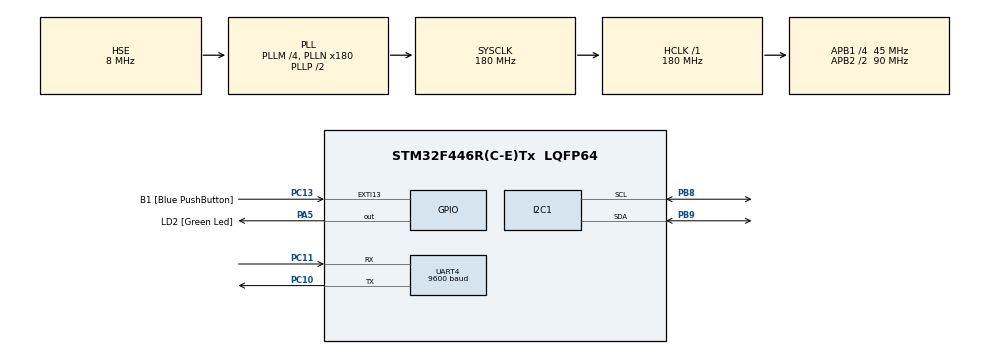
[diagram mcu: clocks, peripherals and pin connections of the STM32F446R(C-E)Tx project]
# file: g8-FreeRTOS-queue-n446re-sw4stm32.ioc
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Dma.Request0=UART4_RX
Dma.UART4_RX.0.Direction=DMA_PERIPH_TO_MEMORY
Dma.UART4_RX.0.FIFOMode=DMA_FIFOMODE_DISABLE
Dma.UART4_RX.0.Instance=DMA1_Stream2
Dma.UART4_RX.0.MemDataAlignment=DMA_MDATAALIGN_BYTE
Dma.UART4_RX.0.MemInc=DMA_MINC_ENABLE
Dma.UART4_RX.0.Mode=DMA_CIRCULAR
Dma.UART4_RX.0.PeriphDataAlignment=DMA_PDATAALIGN_BYTE
Dma.UART4_RX.0.PeriphInc=DMA_PINC_DISABLE
Dma.UART4_RX.0.Priority=DMA_PRIORITY_LOW
FREERTOS.Queues01=mailYPR,16,uint16_t,0,Dynamic,NULL,NULL;mailCMD,16,uint16_t,0,Dynamic,NULL,NULL
FREERTOS.Tasks01=defaultTask,0,128,StartDefaultTask,Default,NULL,Dynamic,NULL,NULL;readSensors,2,512,StartReadSensors,Default,NULL,Dynamic,NULL,NULL;drawBox,-2,512,StartDrawBox,Default,NULL,Dynamic,NULL,NULL;waitCommand,-2,512,StartWaitCommand,Default,NULL,Dynamic,NULL,NULL
I2C1.I2C_Mode=I2C_Fast
Mcu.Family=STM32F4
Mcu.Name=STM32F446R(C-E)Tx
Mcu.Package=LQFP64
NVIC.DMA1_Stream2_IRQn=true\:5\:0\:false\:false\:true\:true\:false
NVIC.PriorityGroup=NVIC_PRIORITYGROUP_4
NVIC.TIM6_DAC_IRQn=true\:0\:0\:false\:false\:true\:false\:false
NVIC.TimeBase=TIM6_DAC_IRQn
NVIC.TimeBaseIP=TIM6
PA13.GPIO_Label=TMS
PA13.Mode=Serial_Wire
PA13.Signal=SYS_JTMS-SWDIO
PA14.GPIO_Label=TCK
PA14.Mode=Serial_Wire
PA14.Signal=SYS_JTCK-SWCLK
PA5.GPIO_Label=LD2 [Green Led]
PA5.Signal=GPIO_Output
PB3.GPIO_Label=SWO
PB3.Signal=SYS_JTDO-SWO
PB8.Mode=I2C
PB8.Signal=I2C1_SCL
PB9.Mode=I2C
PB9.Signal=I2C1_SDA
PC10.Mode=Asynchronous
PC10.Signal=UART4_TX
PC11.Mode=Asynchronous
PC11.Signal=UART4_RX
PC13.GPIO_Label=B1 [Blue PushButton]
PC13.GPIO_ModeDefaultEXTI=GPIO_MODE_IT_FALLING
PC13.Signal=GPXTI13
PC14-OSC32_IN.Mode=LSE-External-Oscillator
PC14-OSC32_IN.Signal=RCC_OSC32_IN
PC15-OSC32_OUT.Mode=LSE-External-Oscillator
PC15-OSC32_OUT.Signal=RCC_OSC32_OUT
PH0-OSC_IN.Mode=HSE-External-Oscillator
PH0-OSC_IN.Signal=RCC_OSC_IN
PH1-OSC_OUT.Mode=HSE-External-Oscillator
PH1-OSC_OUT.Signal=RCC_OSC_OUT
ProjectManager.HeapSize=0x200
ProjectManager.StackSize=0x400
ProjectManager.TargetToolchain=SW4STM32
RCC.48MHZClocksFreq_Value=84000000
RCC.AHBFreq_Value=180000000
RCC.APB1CLKDivider=RCC_HCLK_DIV4
RCC.APB1Freq_Value=45000000
RCC.APB1TimFreq_Value=90000000
RCC.APB2CLKDivider=RCC_HCLK_DIV2
RCC.APB2Freq_Value=90000000
RCC.APB2TimFreq_Value=180000000
RCC.CortexFreq_Value=180000000
RCC.FLatency-AdvancedSettings=FLASH_LATENCY_5
RCC.HCLKFreq_Value=180000000
RCC.HSE_VALUE=8000000
RCC.HSI_VALUE=16000000
RCC.PLLM=4
RCC.PLLN=180
RCC.PLLSourceVirtual=RCC_PLLSOURCE_HSE
RCC.SYSCLKFreq_VALUE=180000000
RCC.SYSCLKSource=RCC_SYSCLKSOURCE_PLLCLK
RCC.USBFreq_Value=180000000
RCC.VCOOutputFreq_Value=360000000
UART4.BaudRate=9600
UART4.VirtualMode=Asynchronous
VP_FREERTOS_VS_ENABLE.Mode=Enabled
VP_SYS_VS_tim6.Mode=TIM6
board=NUCLEO-F446RE

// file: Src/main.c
/**
  ******************************************************************************
  * @file           : main.c
  * @brief          : Main program body
  ******************************************************************************
  * This notice applies to any and all portions of this file
  * that are not between comment pairs USER CODE BEGIN and
  * USER CODE END. Other portions of this file, whether
  * inserted by the user or by software development tools
  * are owned by their respective copyright owners.
  *
  * Copyright (c) 2018 STMicroelectronics International N.V.
  * All rights reserved.
  *
  * Redistribution and use in source and binary forms, with or without
  * modification, are permitted, provided that the following conditions are met:
  *
  * 1. Redistribution of source code must retain the above copyright notice,
  *    this list of conditions and the following disclaimer.
  * 2. Redistributions in binary form must reproduce the above copyright notice,
  *    this list of conditions and the following disclaimer in the documentation
  *    and/or other materials provided with the distribution.
  * 3. Neither the name of STMicroelectronics nor the names of other
  *    contributors to this software may be used to endorse or promote products
  *    derived from this software without specific written permission.
  * 4. This software, including modifications and/or derivative works of this
  *    software, must execute solely and exclusively on microcontroller or
  *    microprocessor devices manufactured by or for STMicroelectronics.
  * 5. Redistribution and use of this software other than as permitted under
  *    this license is void and will automatically terminate your rights under
  *    this license.
  *
  * THIS SOFTWARE IS PROVIDED BY STMICROELECTRONICS AND CONTRIBUTORS "AS IS"
  * AND ANY EXPRESS, IMPLIED OR STATUTORY WARRANTIES, INCLUDING, BUT NOT
  * LIMITED TO, THE IMPLIED WARRANTIES OF MERCHANTABILITY, FITNESS FOR A
  * PARTICULAR PURPOSE AND NON-INFRINGEMENT OF THIRD PARTY INTELLECTUAL PROPERTY
  * RIGHTS ARE DISCLAIMED TO THE FULLEST EXTENT PERMITTED BY LAW. IN NO EVENT
  * SHALL STMICROELECTRONICS OR CONTRIBUTORS BE LIABLE FOR ANY DIRECT, INDIRECT,
  * INCIDENTAL, SPECIAL, EXEMPLARY, OR CONSEQUENTIAL DAMAGES (INCLUDING, BUT NOT
  * LIMITED TO, PROCUREMENT OF SUBSTITUTE GOODS OR SERVICES; LOSS OF USE, DATA,
  * OR PROFITS; OR BUSINESS INTERRUPTION) HOWEVER CAUSED AND ON ANY THEORY OF
  * LIABILITY, WHETHER IN CONTRACT, STRICT LIABILITY, OR TORT (INCLUDING
  * NEGLIGENCE OR OTHERWISE) ARISING IN ANY WAY OUT OF THE USE OF THIS SOFTWARE,
  * EVEN IF ADVISED OF THE POSSIBILITY OF SUCH DAMAGE.
  *
  ******************************************************************************
  */
#include "main.h"
#include "stm32f4xx_hal.h"
#include "cmsis_os.h"
#include "dma.h"
#include "i2c.h"
#include "usart.h"
#include "gpio.h"

/* USER CODE BEGIN PV */
/* Private variables ---------------------------------------------------------*/

/* USER CODE END PV */

void SystemClock_Config(void);
void MX_FREERTOS_Init(void);

/* USER CODE BEGIN PFP */
/* Private function prototypes -----------------------------------------------*/

/* USER CODE END PFP */

int main(void)
{

  /* MCU Configuration----------------------------------------------------------*/

  /* Reset of all peripherals, Initializes the Flash interface and the Systick. */
  HAL_Init();

  /* Configure the system clock */
  SystemClock_Config();

  /* Initialize all configured peripherals */
  MX_GPIO_Init();
  MX_DMA_Init();
  MX_I2C1_Init();
  MX_UART4_Init();

  /* Call init function for freertos objects (in freertos.c) */
  MX_FREERTOS_Init();

  /* Start scheduler */
  osKernelStart();

  /* We should never get here as control is now taken by the scheduler */

  /* Infinite loop */
  while (1)
  {

  }

}

void SystemClock_Config(void)
{

  RCC_OscInitTypeDef RCC_OscInitStruct;
  RCC_ClkInitTypeDef RCC_ClkInitStruct;

    /**Configure the main internal regulator output voltage
    */
  __HAL_RCC_PWR_CLK_ENABLE();

  __HAL_PWR_VOLTAGESCALING_CONFIG(PWR_REGULATOR_VOLTAGE_SCALE1);

    /**Initializes the CPU, AHB and APB busses clocks
    */
  RCC_OscInitStruct.OscillatorType = RCC_OSCILLATORTYPE_HSE;
  RCC_OscInitStruct.HSEState = RCC_HSE_ON;
  RCC_OscInitStruct.PLL.PLLState = RCC_PLL_ON;
  RCC_OscInitStruct.PLL.PLLSource = RCC_PLLSOURCE_HSE;
  RCC_OscInitStruct.PLL.PLLM = 4;
  RCC_OscInitStruct.PLL.PLLN = 180;
  RCC_OscInitStruct.PLL.PLLP = RCC_PLLP_DIV2;
  RCC_OscInitStruct.PLL.PLLQ = 2;
  RCC_OscInitStruct.PLL.PLLR = 2;
  if (HAL_RCC_OscConfig(&RCC_OscInitStruct) != HAL_OK)
  {
    _Error_Handler(__FILE__, __LINE__);
  }

    /**Activate the Over-Drive mode
    */
  if (HAL_PWREx_EnableOverDrive() != HAL_OK)
  {
    _Error_Handler(__FILE__, __LINE__);
  }

    /**Initializes the CPU, AHB and APB busses clocks
    */
  RCC_ClkInitStruct.ClockType = RCC_CLOCKTYPE_HCLK|RCC_CLOCKTYPE_SYSCLK
                              |RCC_CLOCKTYPE_PCLK1|RCC_CLOCKTYPE_PCLK2;
  RCC_ClkInitStruct.SYSCLKSource = RCC_SYSCLKSOURCE_PLLCLK;
  RCC_ClkInitStruct.AHBCLKDivider = RCC_SYSCLK_DIV1;
  RCC_ClkInitStruct.APB1CLKDivider = RCC_HCLK_DIV4;
  RCC_ClkInitStruct.APB2CLKDivider = RCC_HCLK_DIV2;

  if (HAL_RCC_ClockConfig(&RCC_ClkInitStruct, FLASH_LATENCY_5) != HAL_OK)
  {
    _Error_Handler(__FILE__, __LINE__);
  }

    /**Configure the Systick interrupt time
    */
  HAL_SYSTICK_Config(HAL_RCC_GetHCLKFreq()/1000);

    /**Configure the Systick
    */
  HAL_SYSTICK_CLKSourceConfig(SYSTICK_CLKSOURCE_HCLK);

  /* SysTick_IRQn interrupt configuration */
  HAL_NVIC_SetPriority(SysTick_IRQn, 15, 0);
}

void HAL_TIM_PeriodElapsedCallback(TIM_HandleTypeDef *htim)
{
  if (htim->Instance == TIM6) {
    HAL_IncTick();
  }
}

void _Error_Handler(char *file, int line)
{
  while(1)
  {
  }
}

/************************ (C) COPYRIGHT STMicroelectronics *****END OF FILE****/

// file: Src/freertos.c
/**
  ******************************************************************************
  * File Name          : freertos.c
  * Description        : Code for freertos applications
  ******************************************************************************
  * This notice applies to any and all portions of this file
  * that are not between comment pairs USER CODE BEGIN and
  * USER CODE END. Other portions of this file, whether
  * inserted by the user or by software development tools
  * are owned by their respective copyright owners.
  *
  * Copyright (c) 2018 STMicroelectronics International N.V.
  * All rights reserved.
  *
  * Redistribution and use in source and binary forms, with or without
  * modification, are permitted, provided that the following conditions are met:
  *
  * 1. Redistribution of source code must retain the above copyright notice,
  *    this list of conditions and the following disclaimer.
  * 2. Redistributions in binary form must reproduce the above copyright notice,
  *    this list of conditions and the following disclaimer in the documentation
  *    and/or other materials provided with the distribution.
  * 3. Neither the name of STMicroelectronics nor the names of other
  *    contributors to this software may be used to endorse or promote products
  *    derived from this software without specific written permission.
  * 4. This software, including modifications and/or derivative works of this
  *    software, must execute solely and exclusively on microcontroller or
  *    microprocessor devices manufactured by or for STMicroelectronics.
  * 5. Redistribution and use of this software other than as permitted under
  *    this license is void and will automatically terminate your rights under
  *    this license.
  *
  * THIS SOFTWARE IS PROVIDED BY STMICROELECTRONICS AND CONTRIBUTORS "AS IS"
  * AND ANY EXPRESS, IMPLIED OR STATUTORY WARRANTIES, INCLUDING, BUT NOT
  * LIMITED TO, THE IMPLIED WARRANTIES OF MERCHANTABILITY, FITNESS FOR A
  * PARTICULAR PURPOSE AND NON-INFRINGEMENT OF THIRD PARTY INTELLECTUAL PROPERTY
  * RIGHTS ARE DISCLAIMED TO THE FULLEST EXTENT PERMITTED BY LAW. IN NO EVENT
  * SHALL STMICROELECTRONICS OR CONTRIBUTORS BE LIABLE FOR ANY DIRECT, INDIRECT,
  * INCIDENTAL, SPECIAL, EXEMPLARY, OR CONSEQUENTIAL DAMAGES (INCLUDING, BUT NOT
  * LIMITED TO, PROCUREMENT OF SUBSTITUTE GOODS OR SERVICES; LOSS OF USE, DATA,
  * OR PROFITS; OR BUSINESS INTERRUPTION) HOWEVER CAUSED AND ON ANY THEORY OF
  * LIABILITY, WHETHER IN CONTRACT, STRICT LIABILITY, OR TORT (INCLUDING
  * NEGLIGENCE OR OTHERWISE) ARISING IN ANY WAY OUT OF THE USE OF THIS SOFTWARE,
  * EVEN IF ADVISED OF THE POSSIBILITY OF SUCH DAMAGE.
  *
  ******************************************************************************
  */

#include "FreeRTOS.h"
#include "task.h"
#include "cmsis_os.h"

/* USER CODE BEGIN Includes */
#include "stm32f4xx_hal.h"
#include "i2c.h"
#include "mpu.h"
#include "MadgwickAHRS.h"
#include "3Dbox.h"
#include "ringbuffer_dma.h"
/* USER CODE END Includes */

osThreadId defaultTaskHandle;
osThreadId readSensorsHandle;
osThreadId drawBoxHandle;
osThreadId waitCommandHandle;
osMessageQId mailYPRHandle;
osMessageQId mailCMDHandle;

/* USER CODE BEGIN Variables */
/* Data structure for MPU9250 angles */
typedef struct {
	float yaw, pitch, roll;
} YPR;

/* Data structure for bluetooth commands */
typedef struct {
	char command[16];
	uint16_t arg[3];
} CMD;

/* USER CODE END Variables */

void StartDefaultTask(void const * argument);
void StartReadSensors(void const * argument);
void StartDrawBox(void const * argument);
void StartWaitCommand(void const * argument);

void MX_FREERTOS_Init(void); /* (MISRA C 2004 rule 8.1) */

/* Hook prototypes */

/* Init FreeRTOS */

void MX_FREERTOS_Init(void) {

  /* Create the thread(s) */
  /* definition and creation of defaultTask */
  osThreadDef(defaultTask, StartDefaultTask, osPriorityNormal, 0, 128);
  defaultTaskHandle = osThreadCreate(osThread(defaultTask), NULL);

  /* definition and creation of readSensors */
  osThreadDef(readSensors, StartReadSensors, osPriorityHigh, 0, 512);
  readSensorsHandle = osThreadCreate(osThread(readSensors), NULL);

  /* definition and creation of drawBox */
  osThreadDef(drawBox, StartDrawBox, osPriorityLow, 0, 512);
  drawBoxHandle = osThreadCreate(osThread(drawBox), NULL);

  /* definition and creation of waitCommand */
  osThreadDef(waitCommand, StartWaitCommand, osPriorityLow, 0, 512);
  waitCommandHandle = osThreadCreate(osThread(waitCommand), NULL);

  /* Create the queue(s) */
  /* definition and creation of mailYPR */
  osMessageQDef(mailYPR, 16, uint16_t);
  mailYPRHandle = osMessageCreate(osMessageQ(mailYPR), NULL);

  /* definition and creation of mailCMD */
  osMessageQDef(mailCMD, 16, uint16_t);
  mailCMDHandle = osMessageCreate(osMessageQ(mailCMD), NULL);

}

/* StartDefaultTask function */
void StartDefaultTask(void const * argument)
{

  for(;;)
  {
    osDelay(1);
  }
}

/* StartReadSensors function */
void StartReadSensors(void const * argument)
{
  for(;;)
  {
    osDelay(1);
  }
}

/* StartDrawBox function */
void StartDrawBox(void const * argument)
{
  for(;;)
  {
    osDelay(1);
  }
}

/* StartWaitCommand function */
void StartWaitCommand(void const * argument)
{
  for(;;)
  {
    osDelay(1);
  }
}

/************************ (C) COPYRIGHT STMicroelectronics *****END OF FILE****/
